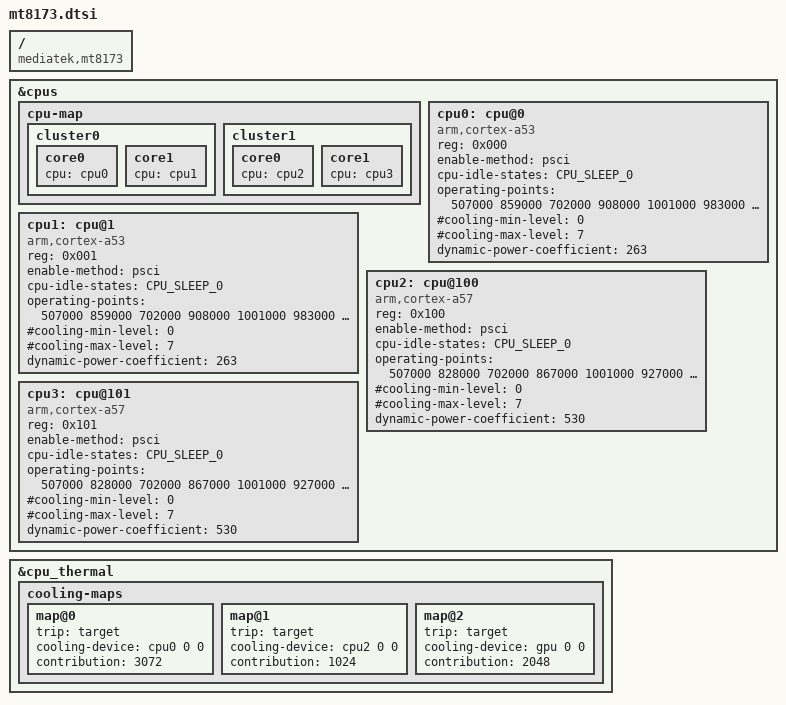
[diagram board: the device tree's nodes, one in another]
/*
 * Copyright (c) 2014 MediaTek Inc.
 * Author: Eddie Huang <eddie.huang@mediatek.com>
 *
 * This program is free software; you can redistribute it and/or modify
 * it under the terms of the GNU General Public License version 2 as
 * published by the Free Software Foundation.
 *
 * This program is distributed in the hope that it will be useful,
 * MERCHANTABILITY or FITNESS FOR A PARTICULAR PURPOSE.  See the
 * GNU General Public License for more details.
 */

#include "mt817x.dtsi"

/ {
	compatible = "mediatek,mt8173";
};

&cpus {
	cpu-map {
		cluster0 {
			core0 {
				cpu = <&cpu0>;
			};
			core1 {
				cpu = <&cpu1>;
			};
		};

		cluster1 {
			core0 {
				cpu = <&cpu2>;
			};
			core1 {
				cpu = <&cpu3>;
			};
		};
	};

	cpu0: cpu@0 {
		device_type = "cpu";
		compatible = "arm,cortex-a53";
		reg = <0x000>;
		enable-method = "psci";
		cpu-idle-states = <&CPU_SLEEP_0>;
		operating-points = <
			507000  859000
			702000  908000
			1001000 983000
			1105000 1009000
			1209000 1034000
			1300000 1057000
			1508000 1109000
			1703000 1125000
		>;
		#cooling-cells = <2>;
		#cooling-min-level = <0>;
		#cooling-max-level = <7>;
		dynamic-power-coefficient = <263>;
	};

	cpu1: cpu@1 {
		device_type = "cpu";
		compatible = "arm,cortex-a53";
		reg = <0x001>;
		enable-method = "psci";
		cpu-idle-states = <&CPU_SLEEP_0>;
		operating-points = <
			507000  859000
			702000  908000
			1001000 983000
			1105000 1009000
			1209000 1034000
			1300000 1057000
			1508000 1109000
			1703000 1125000
		>;
		#cooling-cells = <2>;
		#cooling-min-level = <0>;
		#cooling-max-level = <7>;
		dynamic-power-coefficient = <263>;
	};

	cpu2: cpu@100 {
		device_type = "cpu";
		compatible = "arm,cortex-a57";
		reg = <0x100>;
		enable-method = "psci";
		cpu-idle-states = <&CPU_SLEEP_0>;
		operating-points = <
			507000  828000
			702000  867000
			1001000 927000
			1209000 968000
			1404000 1007000
			1612000 1049000
			1807000 1089000
			2106000 1125000
		>;
		#cooling-cells = <2>;
		#cooling-min-level = <0>;
		#cooling-max-level = <7>;
		dynamic-power-coefficient = <530>;
	};

	cpu3: cpu@101 {
		device_type = "cpu";
		compatible = "arm,cortex-a57";
		reg = <0x101>;
		enable-method = "psci";
		cpu-idle-states = <&CPU_SLEEP_0>;
		operating-points = <
			507000  828000
			702000  867000
			1001000 927000
			1209000 968000
			1404000 1007000
			1612000 1049000
			1807000 1089000
			2106000 1125000
		>;
		#cooling-cells = <2>;
		#cooling-min-level = <0>;
		#cooling-max-level = <7>;
		dynamic-power-coefficient = <530>;
	};
};

&cpu_thermal {
	cooling-maps {
		map@0 {
			trip = <&target>;
			cooling-device = <&cpu0 0 0>;
			contribution = <3072>;
		};
		map@1 {
			trip = <&target>;
			cooling-device = <&cpu2 0 0>;
			contribution = <1024>;
		};
		map@2 {
			trip = <&target>;
			cooling-device = <&gpu 0 0>;
			contribution = <2048>;
		};
	};
};
